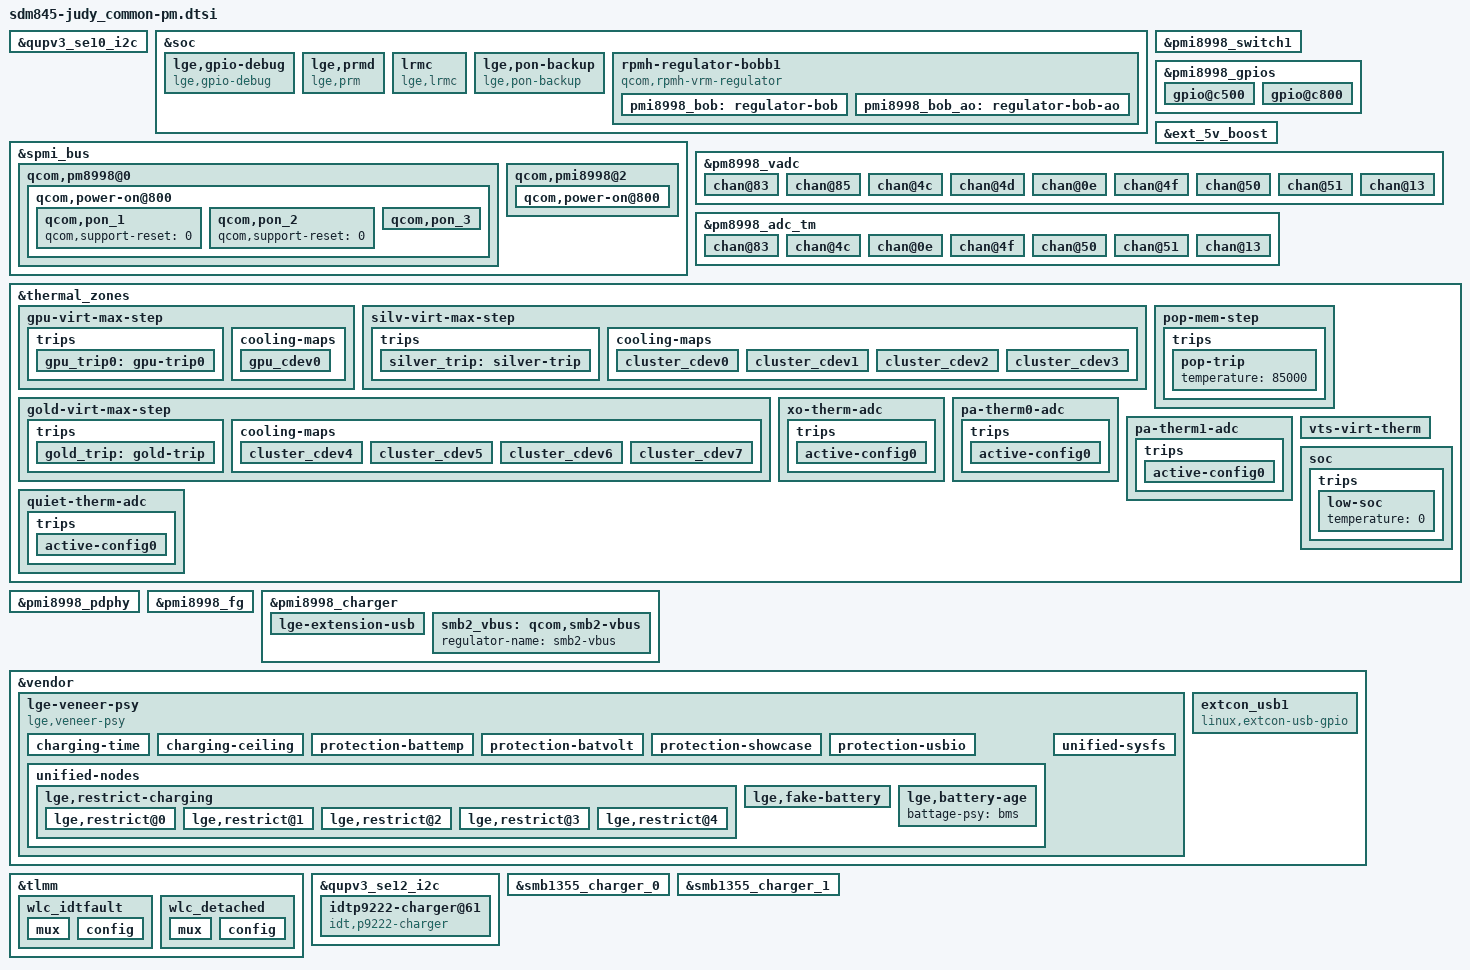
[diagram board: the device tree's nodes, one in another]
/* Copyright (c) 2017, The Linux Foundation. All rights reserved.
 *
 * This program is free software; you can redistribute it and/or modify
 * it under the terms of the GNU General Public License version 2 and
 * only version 2 as published by the Free Software Foundation.
 *
 * This program is distributed in the hope that it will be useful,
 * but WITHOUT ANY WARRANTY; without even the implied warranty of
 * MERCHANTABILITY or FITNESS FOR A PARTICULAR PURPOSE.  See the
 * GNU General Public License for more details.
 */
#include <dt-bindings/msm/power-on.h>
#include <dt-bindings/regulator/qcom,rpmh-regulator.h>

&qupv3_se10_i2c {
#include "../../../qcom/smb1355.dtsi"
};

&soc {
	lge,gpio-debug {
		compatible = "lge,gpio-debug";
		reg = <0x03500000 0x900000>;
		reg-names = "tlmm-base";
		lge,n-msm-gpio = <0x96>;  /* SDM845 0 to 149 */
	};

	lge,prmd {
		compatible = "lge,prm";
		lge,vfps-enabled;
		lge,sben-enabled;
		lge,fbcn-enabled;
		lge,triton-enabled;
	};

	lrmc {
		compatible = "lge,lrmc";
		bob_min_voltage    = <3400000>;
		bob_max_voltage    = <3400000>;
		bob_auto_threshold = <100000>;
		bob_pwm_threshold  = <200000>;
		lrmc_bob_vreg-supply = <&pmi8998_bob>;
	};

	lge,pon-backup {
		compatible = "lge,pon-backup";
		lge,pmic-name =
			"PM8998",
			"PMI8998",
			"PMI8005";
		lge,regulator-table = <
		/*                 SPMS LDO BOB */
		/* 0 - PM845   */   13  29   0
		/* 1 - PMI8998 */    0   0   0
		/* 2 - PM8005  */    4   0   0 >;
	};
};

&soc {
	rpmh-regulator-bobb1 {
		compatible = "qcom,rpmh-vrm-regulator";
		mboxes = <&apps_rsc 0>;
		qcom,resource-name = "bobb1";
		qcom,send-defaults;
		qcom,supported-modes =
			<RPMH_REGULATOR_MODE_PASS
			 RPMH_REGULATOR_MODE_AUTO
			 RPMH_REGULATOR_MODE_HPM>;
		qcom,mode-threshold-currents = <0 100000 200000>;

		pmi8998_bob: regulator-bob {
			regulator-name = "pmi8998_bob";
			qcom,set = <RPMH_REGULATOR_SET_ALL>;
			regulator-min-microvolt = <3312000>;
			regulator-max-microvolt = <3960000>;
			qcom,init-voltage = <3312000>;
			qcom,init-mode = <RPMH_REGULATOR_MODE_PASS>;
		};

		pmi8998_bob_ao: regulator-bob-ao {
			regulator-name = "pmi8998_bob_ao";
			qcom,set = <RPMH_REGULATOR_SET_ACTIVE>;
			regulator-min-microvolt = <3312000>;
			regulator-max-microvolt = <3960000>;
			qcom,init-voltage = <3312000>;
			qcom,init-mode = <RPMH_REGULATOR_MODE_AUTO>;
		};
	};
};

&spmi_bus {
	qcom,pm8998@0 {
		qcom,power-on@800 {
			qcom,s3-debounce = <32>;
			qcom,s3-src = "kpdpwr-and-resin";

			qcom,pon_1 {
				/* KPD_PWR_N */
				status = "ok";
				qcom,support-reset = <0>;
			};
			qcom,pon_2 {
				/* RESIN_N */
				status = "ok";
				qcom,support-reset = <0>;
			};
			qcom,pon_3 {
				/* KPD_PWR_N AND RESIN_N */
				status = "ok";
				qcom,support-reset = <1>;
				qcom,s1-timer = <6720>;
				qcom,s2-timer = <2000>;
				qcom,s2-type = <PON_POWER_OFF_DVDD_HARD_RESET>;
			};
		};
	};
	qcom,pmi8998@2 {
		qcom,power-on@800 {
			qcom,s3-debounce = <128>;
			qcom,s3-src = "kpdpwr-and-resin";
		};
	};
};

&pmi8998_switch1 {
	pinctrl-names = "led_enable", "led_disable";
	pinctrl-0 = <&flash_led3_front_en>;
	pinctrl-1 = <&flash_led3_front_dis>;
};

&pmi8998_gpios {
	gpio@c500 {  /* GPIO6 - QNOVO_EXT_FET_CTL */
		status = "okay";
		qcom,mode = <1>;
		qcom,pull = <5>;
		qcom,vin-sel = <0>;
		qcom,src-sel = <2>;
		qcom,out-strength = <1>;
		qcom,master-en = <1>;
	};
	gpio@c800 {
		reg = <0xc800 0x100>;
		qcom,pin-num = <9>;
		status = "ok";
		qcom,master-en = <0>;
	};
};

&ext_5v_boost {
	status = "ok";
};

&pm8998_vadc {
	chan@83 {
		label = "vph_pwr";
		reg = <0x83>;
		qcom,decimation = <2>;
		qcom,pre-div-channel-scaling = <1>;
		qcom,calibration-type = "absolute";
		qcom,scale-function = <0>;
		qcom,hw-settle-time = <0>;
		qcom,fast-avg-setup = <0>;
	};

	chan@85 {
		label = "vcoin";
		reg = <0x85>;
		qcom,decimation = <2>;
		qcom,pre-div-channel-scaling = <1>;
		qcom,calibration-type = "absolute";
		qcom,scale-function = <0>;
		qcom,hw-settle-time = <0>;
		qcom,fast-avg-setup = <0>;
	};

	chan@4c {
		label = "xo_therm";
		reg = <0x4c>;
		qcom,decimation = <2>;
		qcom,pre-div-channel-scaling = <0>;
		qcom,calibration-type = "ratiometric";
		qcom,scale-function = <4>;
		qcom,hw-settle-time = <2>;
		qcom,fast-avg-setup = <0>;
	};

	/* AMUX 1 */
	chan@4d {
		label = "pcb_rev";
		reg = <0x4d>;
		qcom,decimation = <0>;
		qcom,pre-div-channel-scaling = <0>;
		qcom,calibration-type = "ratiometric";
		qcom,scale-function = <0>;
		qcom,hw-settle-time = <1>;
		qcom,fast-avg-setup = <0>;
	};

	/* AMUX 2 */
	chan@0e {
		label = "usb_id_lv";
		reg = <0x0e>;
		qcom,decimation = <0>;
		qcom,pre-div-channel-scaling = <0>;
		qcom,calibration-type = "ratiometric";
		qcom,scale-function = <0>;
		qcom,hw-settle-time = <5>;
		qcom,fast-avg-setup = <0>;
	};

	/* AMUX 3 */
	chan@4f {
		label = "pa_therm0";
		reg = <0x4f>;
		qcom,decimation = <2>;
		qcom,pre-div-channel-scaling = <0>;
		qcom,calibration-type = "ratiometric";
		qcom,scale-function = <2>;
		qcom,hw-settle-time = <2>;
		qcom,fast-avg-setup = <0>;
	};

	/* AMUX 4 */
	chan@50 {
		label = "pa_therm1";
		reg = <0x50>;
		qcom,decimation = <2>;
		qcom,pre-div-channel-scaling = <0>;
		qcom,calibration-type = "ratiometric";
		qcom,scale-function = <2>;
		qcom,hw-settle-time = <2>;
		qcom,fast-avg-setup = <0>;
	};

	/* AMUX 5 */
	chan@51 {
		label = "quiet_therm";
		reg = <0x51>;
		qcom,decimation = <2>;
		qcom,pre-div-channel-scaling = <0>;
		qcom,calibration-type = "ratiometric";
		qcom,scale-function = <2>;
		qcom,hw-settle-time = <2>;
		qcom,fast-avg-setup = <0>;
	};

	chan@13 {
		label = "gpio9_adc";
		reg = <0x13>;
		qcom,decimation = <0>;
		qcom,pre-div-channel-scaling = <0>;
		qcom,calibration-type = "ratiometric";
		qcom,scale-function = <0>;
		qcom,hw-settle-time = <5>;
		qcom,fast-avg-setup = <0>;
	};
};

&pm8998_adc_tm {
	chan@83 {
		label = "vph_pwr";
		reg = <0x83>;
		qcom,pre-div-channel-scaling = <1>;
		qcom,calibration-type = "absolute";
		qcom,scale-function = <0>;
		qcom,hw-settle-time = <0>;
		qcom,btm-channel-number = <0x60>;
	};

	chan@4c {
		label = "xo_therm";
		reg = <0x4c>;
		qcom,pre-div-channel-scaling = <0>;
		qcom,calibration-type = "ratiometric";
		qcom,scale-function = <4>;
		qcom,hw-settle-time = <2>;
		qcom,btm-channel-number = <0x78>;
		qcom,thermal-node;
	};

	/* AMUX 2 */
	chan@0e {
		label = "usb_id_lv";
		reg = <0x0e>;
		qcom,btm-channel-number = <0x88>;
		qcom,decimation = <0>;
		qcom,pre-div-channel-scaling = <0>;
		qcom,calibration-type = "ratiometric";
		qcom,scale-function = <0>;
		qcom,hw-settle-time = <5>;
		qcom,fast-avg-setup = <0>;
	};

	/* AMUX 3 */
	chan@4f {
		label = "pa_therm0";
		reg = <0x4f>;
		qcom,decimation = <2>;
		qcom,pre-div-channel-scaling = <0>;
		qcom,calibration-type = "ratiometric";
		qcom,scale-function = <2>;
		qcom,hw-settle-time = <2>;
		qcom,fast-avg-setup = <0>;
		qcom,btm-channel-number = <0x68>;
		qcom,thermal-node;
	};

	/* AMUX 4 */
	chan@50 {
		label = "pa_therm1";
		reg = <0x50>;
		qcom,decimation = <2>;
		qcom,pre-div-channel-scaling = <0>;
		qcom,calibration-type = "ratiometric";
		qcom,scale-function = <2>;
		qcom,hw-settle-time = <2>;
		qcom,fast-avg-setup = <0>;
		qcom,btm-channel-number = <0x70>;
		qcom,thermal-node;
	};

	/* AMUX 5 */
	chan@51 {
		label = "quiet_therm";
		reg = <0x51>;
		qcom,pre-div-channel-scaling = <0>;
		qcom,calibration-type = "ratiometric";
		qcom,scale-function = <2>;
		qcom,hw-settle-time = <2>;
		qcom,btm-channel-number = <0x80>;
		qcom,thermal-node;
	};

	chan@13 {
		label = "gpio9_adc";
		reg = <0x13>;
		qcom,decimation = <0>;
		qcom,pre-div-channel-scaling = <0>;
		qcom,calibration-type = "ratiometric";
		qcom,scale-function = <0>;
		qcom,hw-settle-time = <5>;
		qcom,fast-avg-setup = <0>;
		qcom,btm-channel-number = <0x98>;
	};
};

&thermal_zones {
	 gpu-virt-max-step {
		 polling-delay-passive = <10>;
		 polling-delay = <100>;
		 trips {
			gpu_trip0: gpu-trip0 {
				temperature = <85000>;
				hysteresis = <0>;
				type = "passive";
			};
		 };
		 cooling-maps {
			 gpu_cdev0 {
				 trip = <&gpu_trip0>;
				 cooling-device =
					 <&msm_gpu THERMAL_NO_LIMIT
					            (THERMAL_MAX_LIMIT-1)>;
			 };
		 };
	 };

	 silv-virt-max-step {
		 polling-delay-passive = <10>;
		 polling-delay = <100>;
		 trips {
                        silver_trip: silver-trip {
				temperature = <85000>;
				hysteresis = <0>;
				type = "passive";
			};
		 };
		 cooling-maps {
			 cluster_cdev0 {
				trip = <&silver_trip>;
				cooling-device =
					<&CPU0 THERMAL_NO_LIMIT
					        (THERMAL_MAX_LIMIT-1)>;
			 };
			 cluster_cdev1 {
				trip = <&silver_trip>;
				cooling-device =
					<&CPU1 THERMAL_NO_LIMIT
					        (THERMAL_MAX_LIMIT-1)>;
			 };
			 cluster_cdev2 {
				trip = <&silver_trip>;
				cooling-device =
					<&CPU2 THERMAL_NO_LIMIT
					        (THERMAL_MAX_LIMIT-1)>;
			 };
			 cluster_cdev3 {
				trip = <&silver_trip>;
				cooling-device =
					<&CPU3 THERMAL_NO_LIMIT
					        (THERMAL_MAX_LIMIT-1)>;
			 };
		 };
	 };

	 gold-virt-max-step {
		 polling-delay-passive = <10>;
		 polling-delay = <100>;
		 trips {
                        gold_trip: gold-trip {
				temperature = <85000>;
				hysteresis = <0>;
				type = "passive";
			};
		 };
		 cooling-maps {
			 cluster_cdev4 {
				trip = <&gold_trip>;
				cooling-device =
					<&CPU4 THERMAL_NO_LIMIT
					        (THERMAL_MAX_LIMIT-1)>;
			 };
			 cluster_cdev5 {
				trip = <&gold_trip>;
				cooling-device =
					<&CPU5 THERMAL_NO_LIMIT
					        (THERMAL_MAX_LIMIT-1)>;
			 };
			 cluster_cdev6 {
				trip = <&gold_trip>;
				cooling-device =
					<&CPU6 THERMAL_NO_LIMIT
					        (THERMAL_MAX_LIMIT-1)>;
			 };
			 cluster_cdev7 {
				trip = <&gold_trip>;
				cooling-device =
					<&CPU7 THERMAL_NO_LIMIT
					        (THERMAL_MAX_LIMIT-1)>;
			 };
		 };
	 };

	pop-mem-step {
		trips {
			pop-trip {
			temperature = <85000>;
			};
		};
	};

	xo-therm-adc {
		polling-delay-passive = <0>;
		polling-delay = <0>;
		thermal-sensors = <&pm8998_adc_tm 0x4c>;
		thermal-governor = "user_space";
		wake-capable-sensor;

		trips {
			active-config0 {
			temperature = <125000>;
			hysteresis = <10000>;
			type = "passive";
			};
		};
	};

	pa-therm0-adc {
		polling-delay-passive = <0>;
		polling-delay = <0>;
		thermal-sensors = <&pm8998_adc_tm 0x4f>;
		thermal-governor = "user_space";
		wake-capable-sensor;

		trips {
			active-config0 {
			temperature = <125000>;
			hysteresis = <10000>;
			type = "passive";
			};
		};
	};

	pa-therm1-adc {
		polling-delay-passive = <0>;
		polling-delay = <0>;
		thermal-sensors = <&pm8998_adc_tm 0x50>;
		thermal-governor = "user_space";
		wake-capable-sensor;

		trips {
			active-config0 {
			temperature = <125000>;
			hysteresis = <10000>;
			type = "passive";
			};
		};
	};

	quiet-therm-adc {
		polling-delay-passive = <0>;
		polling-delay = <0>;
		thermal-sensors = <&pm8998_adc_tm 0x51>;
		thermal-governor = "user_space";
		wake-capable-sensor;

		trips {
			active-config0 {
			temperature = <125000>;
			hysteresis = <10000>;
			type = "passive";
			};
		};
	};

	vts-virt-therm {
		polling-delay-passive = <0>;
		polling-delay = <0>;
		thermal-governor = "user_space";
		wake-capable-sensor;
	};

	soc {
		trips {
			low-soc {
				temperature = <0>;
			};
		};
	};
};

&pmi8998_pdphy {
	vbus-supply = <&smb2_vbus>;
	lge,uart-sbu-sel-gpio = <&tlmm 23 0>;
};

&pmi8998_fg {
	qcom,fg-cutoff-voltage = <3200>;
	qcom,fg-cutoff-current = <200>;

	lge,fg-esr-rt-filter-switch-temp = <150 200 250>;
	lge,fg-esr-rt-filter-duration = <2400000 1800000 900000>;
	qcom,fg-esr-tight-rt-filter-micro-pct = <498000>;
	qcom,fg-esr-broad-rt-filter-micro-pct = <498000>;
	qcom,fg-esr-tight-lt-filter-micro-pct = <30000>;
	qcom,fg-esr-broad-lt-filter-micro-pct = <30000>;
	qcom,fg-auto-recharge-soc;
	qcom,fg-recharge-soc-thr = <97>;

	qcom,battery-data = <&lge_batterydata>;
};

&pmi8998_charger {
	io-channels =
		<&pmi8998_rradc 8>,
		<&pmi8998_rradc 10>,
		<&pmi8998_rradc 3>,
		<&pmi8998_rradc 4>,
		<&pmi8998_rradc 5>,
		<&pmi8998_rradc 6>;
	io-channel-names =
		"charger_temp",
		"charger_temp_max",
		"usbin_i",
		"usbin_v",
		"dcin_i",
		"dcin_v";

	qcom,auto-recharge-soc;
	qcom,usbid-vadc = <&pm8998_vadc>;

	bvc-vddcx-supply = <&pm8998_s9_level>;
	bvc-vddcx-minlv = <RPMH_REGULATOR_LEVEL_MIN_SVS>;
	bvc-vddcx-maxlv = <RPMH_REGULATOR_LEVEL_MAX>;

	lge-extension-usb {
		lge,usbid-adc-channel = <0x0e>;		// ADC channel# (refer to pm8998_vadc)
		lge,usbid-adc-range = <30>;		// ADC margin (pct unit)
		lge,usbid-pullup-mvol = <1000>;		// Pull-up voltage
		lge,usbid-pullup-kohm = <200>;		// Pull-up resistance

		lge,feature-moisture-charging = <0>;
	};

	smb2_vbus: qcom,smb2-vbus {
		regulator-name = "smb2-vbus";
	};
};

&vendor {
	lge-veneer-psy {
		compatible = "lge,veneer-psy";
		status = "ok";

		charging-time {
			lge,overstatement-enable = <0>;
			lge,overstatement-weight = <2>;
			lge,overstatement-base = <100>;

			lge,maxcharging-mw-chargerlogo = <15000>;
			lge,maxcharging-mw-normal = <15000>;
		};

		charging-ceiling {
		/*	               iusb ibat  idc  : 0 means UNCEILING */
			lge,unknown = < 450  450  450>;
			lge,float   = < 500  500    0>;
			lge,none    = <   0    0    0>;

			lge,dcp     = <1800    0    0>;
			lge,10k     = <3000    0    0>;
			lge,22k     = <1500    0    0>;
			lge,qc2     = <1800    0    0>;
			lge,qc3     = <1800    0    0>;

			lge,usb2    = < 500    0    0>;
			lge,usb3    = < 900    0    0>;
			lge,cdp     = <1500 1500    0>;
			lge,pd      = <   0    0    0>;

			lge,56k     = <1500  500    0>;
			lge,130k    = <1500  500    0>;
			lge,910k    = <1500  500    0>;

			lge,w5w     = <   0    0  900>;
			lge,w9w     = <   0    0  900>;
		};

		protection-battemp {
			lge,threshold-degc-upto-cool = <30>;
			lge,threshold-degc-upto-good = <120>;
			lge,threshold-degc-upto-warm = <450>;
			lge,threshold-degc-upto-hot = <550>;
			lge,threshold-degc-downto-warm = <520>;
			lge,threshold-degc-downto-good = <430>;
			lge,threshold-degc-downto-cool = <100>;
			lge,threshold-degc-downto-cold = <0>;

			lge,period-ms-emergency	= <10000>;
			lge,period-ms-warning	= <30000>;
			lge,period-ms-normal	= <60000>;

		// parameters for warning status cool and warm
			lge,cool-mv-alert	= <4000>;
			lge,cool-ma-alert	= <500>;	// fixed 500 mA
			lge,cool-ma-pct		= <30>;		// means 0.3C rate

			lge,warm-mv-float	= <4000>;
			lge,warm-ma-pct		= <50>;		// means 0.5C rate

		// parameters for battery protection at chilly status
			lge,chilly-status-support;
			lge,chilly-degc-lowerbound = <0>;
			lge,chilly-degc-upperbound = <200>;
			lge,chilly-mv-alert	   = <4000>;
			lge,chilly-ma-alert	   = <630>;
			lge,chilly-ma-pct	   = <50>; 	// means 0.5C rate under batvol 4V
		};

		protection-batvolt {
			lge,threshold-vbat-limit = <4250>;
			lge,threshold-vbat-clear = <4200>;
			lge,threshold-ibat-pct = <70>;	// means 0.7C rate

			lge,step-ibat-ma = <100>;
			lge,step-poll-ms = <5000>;
		};

		protection-showcase {
			lge,soc-range-vzw     = <30 35>;
			lge,soc-range-default = <45 50>;
		};

		protection-usbio {

		};

		unified-nodes {
			lge,feature-charging-parallel = <1>;
			lge,feature-charging-highspeed = <1>;

			lge,restrict-charging {
				// restrict-values 0 means UNCEILING

				lge,restrict@0 {
					restrict-name = "LCD";
					restrict-type = "ibat";
					restrict-commands = "ON", "OFF";
					restrict-values = <1000      0>;
				};
				lge,restrict@1 {
					restrict-name = "CALL";
					restrict-type = "ibat";
					restrict-commands = "ON", "OFF";
					restrict-values = < 500      0>;
				};
				lge,restrict@2 {
					restrict-name = "UHDREC";
					restrict-type = "ibat";
					restrict-commands = "ON", "OFF";
					restrict-values = < 500      0>;
				};
				lge,restrict@3 {
					restrict-name = "WFD";
					restrict-type = "ibat";
					restrict-commands = "ON", "OFF";
					restrict-values = < 500      0>;
				};
				lge,restrict@4 {
					restrict-name = "TDMB";
					restrict-type = "ibat";
					restrict-commands = "MODE1", "MODE2", "OFF";
					restrict-values = <    500      300      0>;
				};
			};

			lge,fake-battery {
				fakebatt-psy = "bms";		// What 'psy' does implement(or support) the fake battery?
				fakebatt-temperature = <400>;
				fakebatt-mvoltage = <4000>;
				fakebatt-capacity = <80>;
			};

			lge,battery-age {
				battage-psy = "bms";		// What 'psy' does implement(or support) the battery age?
			};
		};

		unified-sysfs {
			lge,symlink-map =
			/* group , user_node, kernel node */
			/* Charger */
			"charger",                     "ac_online", "NULL",
			"charger",                    "usb_online", "/sys/class/power_supply/usb/online",	/* TODO */
			"charger",                       "present", "/sys/class/power_supply/usb/present",
			"charger",                    "wlc_online", "/sys/class/power_supply/wireless/online",
			"charger",                          "type", "/sys/class/power_supply/usb/real_type",
			"charger",                      "time_out", "/sys/class/power_supply/battery/safety_timer_enabled",
			"charger",              "charging_enabled", "/sys/devices/platform/lge-unified-nodes/charging_enable",
			"charger",                  "ibat_current", "/sys/class/power_supply/battery/current_now",
			"charger",                  "ichg_current", "/sys/class/power_supply/usb/current_max",
			"charger",                  "iusb_control", "NULL",
			"charger",            "thermal_mitigation", "NULL",
			"charger",        "wlc_thermal_mitigation", "/sys/class/power_supply/dc/current_max",
			"charger",       "usb_parallel_chg_status", "NULL",
			"charger", "usb_parallel_charging_enabled", "/sys/class/power_supply/parallel/charging_enabled",
			"charger", "factory_parallel_charger_test", "/sys/devices/platform/lge-unified-nodes/support_fastpl",
			"charger",            "moisture_detection", "/sys/class/power_supply/usb/moisture_detected",
			"charger",           "restricted_charging", "/sys/devices/platform/lge-unified-nodes/charging_restriction",
			"charger",              "ibat_max_current", "/sys/class/power_supply/battery/constant_charge_current_max",
			"charger",                       "chgstep", "/sys/devices/platform/lge-unified-nodes/charging_step",
			"charger",               "connection_type", "NULL",
			"charger",                       "fastchg", "/sys/devices/platform/lge-unified-nodes/charger_highspeed",
			"charger",         "input_current_settled", "/sys/class/power_supply/usb/input_current_settled",
			"charger",            "store_demo_enabled", "NULL",
			"charger",     "wireless_charging_enabled", "/sys/class/power_supply/wireless/charging_enabled",
			"charger",                 "input_suspend", "/sys/class/power_supply/battery/input_suspend",
			"charger",                  "incompatible", "/sys/devices/platform/lge-unified-nodes/charger_incompatible",
			"charger",                    "hvdcp_fake", "/sys/devices/platform/lge-unified-nodes/fake_hvdcp",
			"charger",               "usb_current_max", "/sys/devices/platform/lge-unified-nodes/fake_sdpmax",
			"charger",               "fastchg_support", "/sys/devices/platform/lge-unified-nodes/support_fastchg",
			"charger",                    "usbid_type", "/sys/class/power_supply/usb/resistance_id",
			/* ADC/MPP */
			"adc",              "thermal", "/sys/class/thermal/",
			"adc",             "xo_therm", "/sys/class/hwmon/hwmon1/device/xo_therm",
			"adc",           "batt_therm", "/sys/class/power_supply/battery/temp",
			"adc",              "batt_id", "/sys/devices/platform/lge-unified-nodes/battery_valid",
			"adc",            "pa_therm0", "/sys/class/hwmon/hwmon1/device/pa_therm0",
			"adc",            "pa_therm1", "/sys/class/hwmon/hwmon1/device/pa_therm1",
			"adc",           "quiet_therm","/sys/class/hwmon/hwmon1/device/quiet_therm",
			"adc",               "usb_in", "/sys/class/power_supply/usb/voltage_now",
			"adc",                "vcoin", "/sys/class/hwmon/hwmon1/device/vcoin",
			"adc",              "vph_pwr", "/sys/class/hwmon/hwmon1/device/vph_pwr",
			"adc",               "usb_id", "/sys/devices/platform/lge-unified-nodes/charger_usbid",
			"adc",             "usb_edge", "NULL",
			"adc",                 "pmic", "/sys/class/thermal/thermal_zone27/temp",
			"adc",                  "vts", "/sys/bus/platform/drivers/monitor-thermal/soc:lge,monitor-thermal/vts_temp",
			/* Battery */
			"battery",         "capacity", "/sys/class/power_supply/battery/capacity",
			"battery",           "health", "/sys/class/power_supply/battery/health",
			"battery",          "present", "/sys/class/power_supply/battery/present",
			"battery",      "pseudo_batt", "/sys/devices/platform/lge-unified-nodes/fake_battery",
			"battery",           "status", "/sys/class/power_supply/battery/status",
			"battery",       "status_raw", "NULL",
			"battery",             "temp", "/sys/class/power_supply/battery/temp",
			"battery",    "valid_batt_id", "/sys/devices/platform/lge-unified-nodes/battery_valid",
			"battery",      "voltage_now", "/sys/class/power_supply/battery/voltage_now",
			"battery",          "vzw_chg", "/sys/devices/platform/lge-unified-nodes/charger_verbose",
			"battery",     "raw_capacity", "/sys/class/power_supply/bms/capacity_raw",
			"battery",        "condition", "/sys/devices/platform/lge-unified-nodes/battery_condition",
			"battery",      "battery_age", "/sys/devices/platform/lge-unified-nodes/battery_age",
			"battery","battery_age_level", "/sys/devices/platform/lge-unified-nodes/battery_age",
			"battery",            "cycle", "/sys/devices/platform/lge-unified-nodes/battery_cycle",
			"battery",     "battery_type", "/sys/class/power_supply/bms/battery_type",
			"battery",      "charge_full", "/sys/class/power_supply/bms/charge_full",
			"battery",   "charge_now_raw", "/sys/class/power_supply/bms/charge_now_raw",
			"battery", "time_to_full_now", "/sys/class/power_supply/battery/time_to_full_now",
			/* LCD Backlight */
			"lcd",           "brightness", "/sys/class/backlight/panel0-backlight/brightness",
			"lcd",       "max_brightness", "/sys/class/backlight/panel0-backlight/max_brightness",
			"lcd_ex",        "brightness", "NULL",
			"lcd_ex",    "max_brightness", "NULL",
			/* KEY LED */
			"key_led",   "red_brightness", "/sys/class/leds/red/brightness",
			"key_led", "green_brightness", "/sys/class/leds/green/brightness",
			"key_led",  "blue_brightness", "/sys/class/leds/blue/brightness",
			"key_led",  "setting",         "/sys/class/lg_rgb_led/use_patterns/setting",
			/* CPU */
			"cpu",       "cpu_idle_modes", "NULL",
			/* GPU */
			"gpu",                 "busy", "/sys/class/kgsl/kgsl-3d0/gpubusy",
			"gpu",               "gpuclk", "/sys/class/kgsl/kgsl-3d0/gpuclk",
			/* PLATFORM */
			"platform",       "speed_bin", "NULL",
			"platform",         "pvs_bin", "NULL",
			"platform",     "power_state", "/sys/power/autosleep",
			"platform",   "poweron_alarm", "/sys/module/qpnp_rtc/parameters/poweron_alarm",
			"platform",         "pcb_rev", "/sys/class/hwmon/hwmon1/device/pcb_rev",
			"platform",       "smpl_boot", "/sys/module/lge_smpl_count/parameters/smpl_boot",
			/* testmode */
			"testmode",            "temp", "/sys/class/power_supply/battery/temp",
			"testmode",     "voltage_now", "/sys/class/power_supply/battery/voltage_now",
			"testmode",          "usb_id", "/sys/devices/platform/lge-unified-nodes/charger_usbid",
			"testmode",         "batt_id", "/sys/devices/platform/lge-unified-nodes/battery_valid",
			"testmode",         "fuelval", "/sys/class/power_supply/battery/capacity",
			"testmode",        "xo_therm", "/sys/class/hwmon/hwmon1/device/xo_therm",
			"testmode",          "charge", "/sys/class/power_supply/battery/battery_charging_enabled",
			"testmode",          "chcomp", "/sys/devices/platform/lge-unified-nodes/charging_completed",
			"testmode",           "usbin", "/sys/class/power_supply/usb/voltage_now",
			"testmode",       "pa_therm0", "/sys/class/hwmon/hwmon1/device/pa_therm1",
			"testmode",       "pa_therm1", "/sys/class/hwmon/hwmon1/device/pa_therm2",
			"testmode",       "bd_therm2", "/sys/class/hwmon/hwmon1/device/quiet_therm",
			"testmode",           "vcoin", "/sys/class/hwmon/hwmon1/device/vcoin",
			"testmode",         "vph_pwr", "/sys/class/hwmon/hwmon1/device/vph_pwr",
			"testmode",     "current_now", "/sys/class/power_supply/battery/current_now",
			"testmode",     "current_max", "/sys/class/power_supply/usb/current_max",
			"testmode",         "pcb_rev", "/sys/class/hwmon/hwmon1/device/pcb_rev",
			"testmode",      "chgmodeoff", "/sys/class/power_supply/battery/input_suspend",
			"testmode",         "fuelrst", "/sys/class/power_supply/battery/present",
			"testmode",        "rtc_time", "/dev/rtc0",
			"testmode",           "pmrst", "NULL",
			"testmode",        "battexit", "/sys/class/power_supply/battery/present",
			"testmode",  "hardreset_mode", "NULL",
			/* ps feature*/
			"psfeature",     "vfps_ratio", "/sys/class/power/vfps/vfps_ratio",
			"psfeature",           "vfps", "/sys/class/power/vfps/vfps",
			"psfeature",      "vfps_fcnt", "/sys/class/power/vfps/vfps_fcnt",
			"psfeature",  "triton_policy", "/sys/class/power/triton/cur_policy",
			"psfeature",   "cancun_is_cm", "NULL",
			"regulator",       "vreg_bob", "/sys/devices/platform/soc/soc:lrmc/bob_mode";
		};
	};

	extcon_usb1: extcon_usb1 {
		compatible = "linux,extcon-usb-gpio";
		vbus-gpio = <&pmi8998_gpios 8 GPIO_ACTIVE_HIGH>;

		pinctrl-names = "default";
		pinctrl-0 = <&usb2_vbus_det_default>;
	};
};

&tlmm {
	wlc_idtfault: wlc_idtfault {
		mux {
			pins = "gpio52";
			function = "gpio";
		};

		config {
			pins = "gpio52";
			bias-pull-up;
		};
	};

	wlc_detached: wlc_detached {
		mux {
			pins = "gpio37";
			function = "gpio";
		};

		config {
			pins = "gpio37";
			bias-pull-up;
		};
	};
};

&qupv3_se12_i2c {
	idtp9222-charger@61 {				// Slave driver and slave Address
		compatible ="idt,p9222-charger";	// Manufacture, model
		reg = <0x61>;				// Slave Address
		status = "ok";

		// one time calling of pinctrl.
		// pinctrl-0 is the permanent configuraion of MSM GPIOs
		pinctrl-names = "wlc_pinctrl";
		pinctrl-0 = <&wlc_idtfault &wlc_detached>;

		idt,gpio-idtfault = <&tlmm 52 0>;
		idt,gpio-detached = <&tlmm 37 0>;
		idt,gpio-disabled = <&pmi8998_gpios 9 0>;

		idt,configure-bppcurr = <900000>;
		idt,configure-eppcurr = <900000>;
		idt,configure-overheat = <450>;		// Temperature threshold to send EPT_BY_OVERTEMP
		idt,configure-sysfs;			// For debug sysfs
	};
};

&smb1355_charger_0 {
	status = "ok";
	qcom,parallel-mode = <3>;
	qcom,disable-ctm;
};

&smb1355_charger_1 {
	status = "ok";
	qcom,parallel-mode = <3>;
	qcom,disable-ctm;
};
